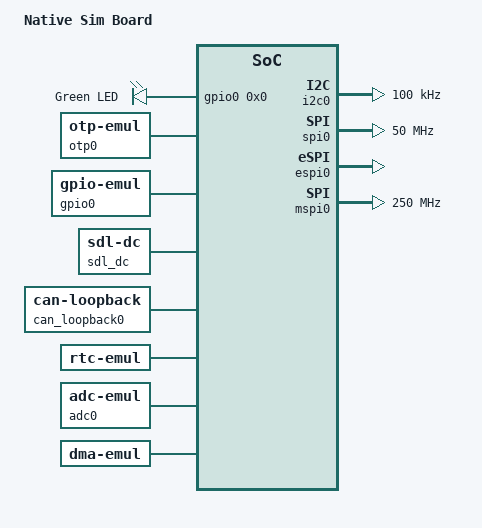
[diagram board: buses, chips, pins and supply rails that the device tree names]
/dts-v1/;

/* node '/' defined in zephyr/dts/common/skeleton.dtsi:9 */
/ {
	#address-cells = < 0x1 >;    /* in zephyr/dts/common/skeleton.dtsi:10 */
	#size-cells = < 0x1 >;       /* in zephyr/dts/common/skeleton.dtsi:11 */
	model = "Native Sim Board";  /* in zephyr/boards/native/native_sim/native_sim.dts:15 */
	compatible = "zephyr,posix"; /* in zephyr/boards/native/native_sim/native_sim.dts:16 */

	/* node '/chosen' defined in zephyr/dts/common/skeleton.dtsi:13 */
	chosen {
		zephyr,console = &uart0;                     /* in zephyr/boards/native/native_sim/native_sim.dts:19 */
		zephyr,shell-uart = &uart0;                  /* in zephyr/boards/native/native_sim/native_sim.dts:20 */
		zephyr,uart-mcumgr = &uart0;                 /* in zephyr/boards/native/native_sim/native_sim.dts:21 */
		zephyr,flash = &flash0;                      /* in zephyr/boards/native/native_sim/native_sim.dts:22 */
		zephyr,entropy = &rng;                       /* in zephyr/boards/native/native_sim/native_sim.dts:23 */
		zephyr,flash-controller = &flashcontroller0; /* in zephyr/boards/native/native_sim/native_sim.dts:24 */
		zephyr,display = &sdl_dc;                    /* in zephyr/boards/native/native_sim/native_sim.dts:25 */
		zephyr,canbus = &can_loopback0;              /* in zephyr/boards/native/native_sim/native_sim.dts:26 */
		zephyr,code-partition = &slot0_partition;    /* in zephyr/boards/native/native_sim/native_sim.dts:27 */
		zephyr,bt-hci = &bt_hci_userchan;            /* in zephyr/boards/native/native_sim/native_sim.dts:28 */
		zephyr,touch = &input_sdl_touch;             /* in zephyr/boards/native/native_sim/native_sim.dts:29 */
	};

	/* node '/aliases' defined in zephyr/dts/common/skeleton.dtsi:15 */
	aliases {
		codec0 = &audio_codec; /* in zephyr/boards/native/native_sim/native_sim.dts:33 */
		dmic0 = &dmic0;        /* in zephyr/boards/native/native_sim/native_sim.dts:34 */
		eeprom-0 = &eeprom0;   /* in zephyr/boards/native/native_sim/native_sim.dts:35 */
		i2c-0 = &i2c0;         /* in zephyr/boards/native/native_sim/native_sim.dts:36 */
		i2s-node0 = &i2s_rxtx; /* in zephyr/boards/native/native_sim/native_sim.dts:37 */
		spi-0 = &spi0;         /* in zephyr/boards/native/native_sim/native_sim.dts:38 */
		led0 = &led0;          /* in zephyr/boards/native/native_sim/native_sim.dts:39 */
		rtc = &rtc;            /* in zephyr/boards/native/native_sim/native_sim.dts:40 */
	};

	/* node '/leds' defined in zephyr/boards/native/native_sim/native_sim.dts:43 */
	leds: leds {
		compatible = "gpio-leds"; /* in zephyr/boards/native/native_sim/native_sim.dts:44 */

		/* node '/leds/led_0' defined in zephyr/boards/native/native_sim/native_sim.dts:46 */
		led0: led_0 {
			gpios = < &gpio0 0x0 0x0 >; /* in zephyr/boards/native/native_sim/native_sim.dts:47 */
			label = "Green LED";        /* in zephyr/boards/native/native_sim/native_sim.dts:48 */
		};
	};

	/* node '/cpus' defined in zephyr/boards/native/native_sim/native_sim.dts:52 */
	cpus {
		#address-cells = < 0x1 >; /* in zephyr/boards/native/native_sim/native_sim.dts:53 */
		#size-cells = < 0x0 >;    /* in zephyr/boards/native/native_sim/native_sim.dts:54 */

		/* node '/cpus/cpu@0' defined in zephyr/boards/native/native_sim/native_sim.dts:56 */
		cpu0: cpu@0 {
			compatible = "zephyr,native-sim-cpu"; /* in zephyr/boards/native/native_sim/native_sim.dts:57 */
			reg = < 0x0 >;                        /* in zephyr/boards/native/native_sim/native_sim.dts:58 */
		};
	};

	/* node '/flash-controller@0' defined in zephyr/boards/native/native_sim/native_sim.dts:62 */
	flashcontroller0: flash-controller@0 {
		compatible = "zephyr,sim-flash"; /* in zephyr/boards/native/native_sim/native_sim.dts:63 */
		reg = < 0x0 0x200000 >;          /* in zephyr/boards/native/native_sim/native_sim.dts:64 */
		ranges;                          /* in zephyr/boards/native/native_sim/native_sim.dts:65 */
		#address-cells = < 0x1 >;        /* in zephyr/boards/native/native_sim/native_sim.dts:67 */
		#size-cells = < 0x1 >;           /* in zephyr/boards/native/native_sim/native_sim.dts:68 */
		erase-value = < 0xff >;          /* in zephyr/boards/native/native_sim/native_sim.dts:69 */

		/* node '/flash-controller@0/flash@0' defined in zephyr/boards/native/native_sim/native_sim.dts:71 */
		flash0: flash@0 {
			status = "okay";               /* in zephyr/boards/native/native_sim/native_sim.dts:72 */
			compatible = "soc-nv-flash";   /* in zephyr/boards/native/native_sim/native_sim.dts:73 */
			erase-block-size = < 0x1000 >; /* in zephyr/boards/native/native_sim/native_sim.dts:74 */
			write-block-size = < 0x1 >;    /* in zephyr/boards/native/native_sim/native_sim.dts:75 */
			reg = < 0x0 0x200000 >;        /* in zephyr/boards/native/native_sim/native_sim.dts:76 */
			ranges = < 0x0 0x0 0x200000 >; /* in zephyr/boards/native/native_sim/native_sim.dts:77 */
			#address-cells = < 0x1 >;      /* in zephyr/boards/native/native_sim/native_sim.dts:78 */
			#size-cells = < 0x1 >;         /* in zephyr/boards/native/native_sim/native_sim.dts:79 */

			/* node '/flash-controller@0/flash@0/partitions' defined in zephyr/boards/native/native_sim/native_sim.dts:81 */
			partitions {
				ranges;                   /* in zephyr/boards/native/native_sim/native_sim.dts:82 */
				#address-cells = < 0x1 >; /* in zephyr/boards/native/native_sim/native_sim.dts:83 */
				#size-cells = < 0x1 >;    /* in zephyr/boards/native/native_sim/native_sim.dts:84 */

				/* node '/flash-controller@0/flash@0/partitions/partition@0' defined in zephyr/boards/native/native_sim/native_sim.dts:86 */
				boot_partition: partition@0 {
					compatible = "zephyr,mapped-partition"; /* in zephyr/boards/native/native_sim/native_sim.dts:87 */
					label = "mcuboot";                      /* in zephyr/boards/native/native_sim/native_sim.dts:88 */
					reg = < 0x0 0xc000 >;                   /* in zephyr/boards/native/native_sim/native_sim.dts:89 */
				};

				/* node '/flash-controller@0/flash@0/partitions/partition@c000' defined in zephyr/boards/native/native_sim/native_sim.dts:92 */
				slot0_partition: partition@c000 {
					compatible = "zephyr,mapped-partition"; /* in zephyr/boards/native/native_sim/native_sim.dts:93 */
					label = "image-0";                      /* in zephyr/boards/native/native_sim/native_sim.dts:94 */
					reg = < 0xc000 0x69000 >;               /* in zephyr/boards/native/native_sim/native_sim.dts:95 */
				};

				/* node '/flash-controller@0/flash@0/partitions/partition@75000' defined in zephyr/boards/native/native_sim/native_sim.dts:98 */
				slot1_partition: partition@75000 {
					compatible = "zephyr,mapped-partition"; /* in zephyr/boards/native/native_sim/native_sim.dts:99 */
					label = "image-1";                      /* in zephyr/boards/native/native_sim/native_sim.dts:100 */
					reg = < 0x75000 0x69000 >;              /* in zephyr/boards/native/native_sim/native_sim.dts:101 */
				};

				/* node '/flash-controller@0/flash@0/partitions/partition@de000' defined in zephyr/boards/native/native_sim/native_sim.dts:104 */
				scratch_partition: partition@de000 {
					compatible = "zephyr,mapped-partition"; /* in zephyr/boards/native/native_sim/native_sim.dts:105 */
					label = "image-scratch";                /* in zephyr/boards/native/native_sim/native_sim.dts:106 */
					reg = < 0xde000 0x1e000 >;              /* in zephyr/boards/native/native_sim/native_sim.dts:107 */
				};

				/* node '/flash-controller@0/flash@0/partitions/partition@fc000' defined in zephyr/boards/native/native_sim/native_sim.dts:110 */
				storage_partition: partition@fc000 {
					compatible = "zephyr,mapped-partition"; /* in zephyr/boards/native/native_sim/native_sim.dts:111 */
					label = "storage";                      /* in zephyr/boards/native/native_sim/native_sim.dts:112 */
					reg = < 0xfc000 0x4000 >;               /* in zephyr/boards/native/native_sim/native_sim.dts:113 */
				};
			};
		};
	};

	/* node '/eeprom' defined in zephyr/boards/native/native_sim/native_sim.dts:119 */
	eeprom0: eeprom {
		status = "okay";                  /* in zephyr/boards/native/native_sim/native_sim.dts:120 */
		compatible = "zephyr,sim-eeprom"; /* in zephyr/boards/native/native_sim/native_sim.dts:121 */
		size = < 0x8000 >;                /* in zephyr/boards/native/native_sim/native_sim.dts:122 */
	};

	/* node '/otp' defined in zephyr/boards/native/native_sim/native_sim.dts:125 */
	otp0: otp {
		compatible = "zephyr,otp-emul"; /* in zephyr/boards/native/native_sim/native_sim.dts:126 */
		size = < 0x400 >;               /* in zephyr/boards/native/native_sim/native_sim.dts:127 */
		status = "okay";                /* in zephyr/boards/native/native_sim/native_sim.dts:128 */
	};

	/* node '/i2c@100' defined in zephyr/boards/native/native_sim/native_sim.dts:131 */
	i2c0: i2c@100 {
		status = "okay";                           /* in zephyr/boards/native/native_sim/native_sim.dts:132 */
		compatible = "zephyr,i2c-emul-controller"; /* in zephyr/boards/native/native_sim/native_sim.dts:133 */
		clock-frequency = < 0x186a0 >;             /* in zephyr/boards/native/native_sim/native_sim.dts:134 */
		#address-cells = < 0x1 >;                  /* in zephyr/boards/native/native_sim/native_sim.dts:135 */
		#size-cells = < 0x0 >;                     /* in zephyr/boards/native/native_sim/native_sim.dts:136 */
		#forward-cells = < 0x1 >;                  /* in zephyr/boards/native/native_sim/native_sim.dts:137 */
		reg = < 0x100 0x4 >;                       /* in zephyr/boards/native/native_sim/native_sim.dts:138 */
	};

	/* node '/spi@200' defined in zephyr/boards/native/native_sim/native_sim.dts:141 */
	spi0: spi@200 {
		status = "okay";                           /* in zephyr/boards/native/native_sim/native_sim.dts:142 */
		compatible = "zephyr,spi-emul-controller"; /* in zephyr/boards/native/native_sim/native_sim.dts:143 */
		clock-frequency = < 0x2faf080 >;           /* in zephyr/boards/native/native_sim/native_sim.dts:144 */
		#address-cells = < 0x1 >;                  /* in zephyr/boards/native/native_sim/native_sim.dts:145 */
		#size-cells = < 0x0 >;                     /* in zephyr/boards/native/native_sim/native_sim.dts:146 */
		reg = < 0x200 0x4 >;                       /* in zephyr/boards/native/native_sim/native_sim.dts:147 */
	};

	/* node '/espi@300' defined in zephyr/boards/native/native_sim/native_sim.dts:150 */
	espi0: espi@300 {
		status = "okay";                            /* in zephyr/boards/native/native_sim/native_sim.dts:151 */
		compatible = "zephyr,espi-emul-controller"; /* in zephyr/boards/native/native_sim/native_sim.dts:152 */
		reg = < 0x300 0x4 >;                        /* in zephyr/boards/native/native_sim/native_sim.dts:153 */
		#address-cells = < 0x1 >;                   /* in zephyr/boards/native/native_sim/native_sim.dts:154 */
		#size-cells = < 0x0 >;                      /* in zephyr/boards/native/native_sim/native_sim.dts:155 */
	};

	/* node '/mspi@400' defined in zephyr/boards/native/native_sim/native_sim.dts:158 */
	mspi0: mspi@400 {
		status = "okay";                            /* in zephyr/boards/native/native_sim/native_sim.dts:159 */
		compatible = "zephyr,mspi-emul-controller"; /* in zephyr/boards/native/native_sim/native_sim.dts:160 */
		clock-frequency = < 0xee6b280 >;            /* in zephyr/boards/native/native_sim/native_sim.dts:161 */
		reg = < 0x400 0x4 >;                        /* in zephyr/boards/native/native_sim/native_sim.dts:162 */
		#address-cells = < 0x1 >;                   /* in zephyr/boards/native/native_sim/native_sim.dts:163 */
		#size-cells = < 0x0 >;                      /* in zephyr/boards/native/native_sim/native_sim.dts:164 */
	};

	/* node '/uart' defined in zephyr/boards/native/native_sim/native_sim.dts:167 */
	uart0: uart {
		status = "okay";                       /* in zephyr/boards/native/native_sim/native_sim.dts:168 */
		compatible = "zephyr,native-pty-uart"; /* in zephyr/boards/native/native_sim/native_sim.dts:169 */
		current-speed = < 0x0 >;               /* in zephyr/boards/native/native_sim/native_sim.dts:173 */
	};

	/* node '/uart_1' defined in zephyr/boards/native/native_sim/native_sim.dts:176 */
	uart1: uart_1 {
		status = "disabled";                   /* in zephyr/boards/native/native_sim/native_sim.dts:177 */
		compatible = "zephyr,native-pty-uart"; /* in zephyr/boards/native/native_sim/native_sim.dts:178 */
		current-speed = < 0x0 >;               /* in zephyr/boards/native/native_sim/native_sim.dts:182 */
	};

	/* node '/rng' defined in zephyr/boards/native/native_sim/native_sim.dts:185 */
	rng: rng {
		status = "okay";                      /* in zephyr/boards/native/native_sim/native_sim.dts:186 */
		compatible = "zephyr,native-sim-rng"; /* in zephyr/boards/native/native_sim/native_sim.dts:187 */
	};

	/* node '/counter' defined in zephyr/boards/native/native_sim/native_sim.dts:190 */
	counter0: counter {
		status = "okay";                          /* in zephyr/boards/native/native_sim/native_sim.dts:191 */
		compatible = "zephyr,native-sim-counter"; /* in zephyr/boards/native/native_sim/native_sim.dts:192 */
		#counter-capture-cells = < 0x2 >;         /* in zephyr/boards/native/native_sim/native_sim.dts:193 */
	};

	/* node '/gpio_emul' defined in zephyr/boards/native/native_sim/native_sim.dts:196 */
	gpio0: gpio_emul {
		status = "okay";                 /* in zephyr/boards/native/native_sim/native_sim.dts:197 */
		compatible = "zephyr,gpio-emul"; /* in zephyr/boards/native/native_sim/native_sim.dts:198 */
		rising-edge;                     /* in zephyr/boards/native/native_sim/native_sim.dts:199 */
		falling-edge;                    /* in zephyr/boards/native/native_sim/native_sim.dts:200 */
		high-level;                      /* in zephyr/boards/native/native_sim/native_sim.dts:201 */
		low-level;                       /* in zephyr/boards/native/native_sim/native_sim.dts:202 */
		gpio-controller;                 /* in zephyr/boards/native/native_sim/native_sim.dts:203 */
		#gpio-cells = < 0x2 >;           /* in zephyr/boards/native/native_sim/native_sim.dts:204 */
		phandle = < 0x1 >;               /* in zephyr/boards/native/native_sim/native_sim.dts:47 */
	};

	/* node '/udc0' defined in zephyr/boards/native/native_sim/native_sim.dts:207 */
	zephyr_udc0: udc0 {
		compatible = "zephyr,native-posix-udc"; /* in zephyr/boards/native/native_sim/native_sim.dts:208 */
	};

	/* node '/sdl_dc' defined in zephyr/boards/native/native_sim/native_sim.dts:211 */
	sdl_dc: sdl_dc {
		compatible = "zephyr,sdl-dc"; /* in zephyr/boards/native/native_sim/native_sim.dts:212 */
		pixel-format = < 0x8 >;       /* in zephyr/boards/native/native_sim/native_sim.dts:213 */
		height = < 0xf0 >;            /* in zephyr/boards/native/native_sim/native_sim.dts:214 */
		width = < 0x140 >;            /* in zephyr/boards/native/native_sim/native_sim.dts:215 */
		phandle = < 0x2 >;            /* in zephyr/boards/native/native_sim/native_sim.dts:220 */
	};

	/* node '/input-sdl-touch' defined in zephyr/boards/native/native_sim/native_sim.dts:218 */
	input_sdl_touch: input-sdl-touch {
		compatible = "zephyr,input-sdl-touch"; /* in zephyr/boards/native/native_sim/native_sim.dts:219 */
		display = < &sdl_dc >;                 /* in zephyr/boards/native/native_sim/native_sim.dts:220 */
	};

	/* node '/can_loopback0' defined in zephyr/boards/native/native_sim/native_sim.dts:223 */
	can_loopback0: can_loopback0 {
		status = "okay";                    /* in zephyr/boards/native/native_sim/native_sim.dts:224 */
		compatible = "zephyr,can-loopback"; /* in zephyr/boards/native/native_sim/native_sim.dts:225 */
	};

	/* node '/can' defined in zephyr/boards/native/native_sim/native_sim.dts:228 */
	can0: can {
		status = "disabled";                    /* in zephyr/boards/native/native_sim/native_sim.dts:229 */
		compatible = "zephyr,native-linux-can"; /* in zephyr/boards/native/native_sim/native_sim.dts:230 */
		host-interface = "zcan0";               /* in zephyr/boards/native/native_sim/native_sim.dts:234 */
	};

	/* node '/rtc' defined in zephyr/boards/native/native_sim/native_sim.dts:237 */
	rtc: rtc {
		status = "okay";                /* in zephyr/boards/native/native_sim/native_sim.dts:238 */
		compatible = "zephyr,rtc-emul"; /* in zephyr/boards/native/native_sim/native_sim.dts:239 */
		alarms-count = < 0x2 >;         /* in zephyr/boards/native/native_sim/native_sim.dts:240 */
	};

	/* node '/adc' defined in zephyr/boards/native/native_sim/native_sim.dts:243 */
	adc0: adc {
		compatible = "zephyr,adc-emul"; /* in zephyr/boards/native/native_sim/native_sim.dts:244 */
		nchannels = < 0x2 >;            /* in zephyr/boards/native/native_sim/native_sim.dts:245 */
		#io-channel-cells = < 0x1 >;    /* in zephyr/boards/native/native_sim/native_sim.dts:246 */
		status = "okay";                /* in zephyr/boards/native/native_sim/native_sim.dts:247 */
	};

	/* node '/audio_codec' defined in zephyr/boards/native/native_sim/native_sim.dts:250 */
	audio_codec: audio_codec {
		compatible = "zephyr,dummy-codec"; /* in zephyr/boards/native/native_sim/native_sim.dts:251 */
		status = "okay";                   /* in zephyr/boards/native/native_sim/native_sim.dts:252 */
	};

	/* node '/dmic0' defined in zephyr/boards/native/native_sim/native_sim.dts:255 */
	dmic0: dmic0 {
		compatible = "zephyr,native-sim-dmic"; /* in zephyr/boards/native/native_sim/native_sim.dts:256 */
		status = "okay";                       /* in zephyr/boards/native/native_sim/native_sim.dts:257 */
	};

	/* node '/i2s_rx' defined in zephyr/boards/native/native_sim/native_sim.dts:260 */
	i2s_rx0: i2s_rx {
		compatible = "zephyr,native-sim-i2s"; /* in zephyr/boards/native/native_sim/native_sim.dts:261 */
		status = "okay";                      /* in zephyr/boards/native/native_sim/native_sim.dts:262 */
		stream-direction = "rx";              /* in zephyr/boards/native/native_sim/native_sim.dts:263 */
	};

	/* node '/i2s_rxtx' defined in zephyr/boards/native/native_sim/native_sim.dts:266 */
	i2s_rxtx: i2s_rxtx {
		compatible = "zephyr,native-sim-i2s"; /* in zephyr/boards/native/native_sim/native_sim.dts:267 */
		status = "okay";                      /* in zephyr/boards/native/native_sim/native_sim.dts:268 */
		stream-direction = "both";            /* in zephyr/boards/native/native_sim/native_sim.dts:269 */
	};

	/* node '/i2s_tx' defined in zephyr/boards/native/native_sim/native_sim.dts:272 */
	i2s_tx0: i2s_tx {
		compatible = "zephyr,native-sim-i2s"; /* in zephyr/boards/native/native_sim/native_sim.dts:273 */
		status = "okay";                      /* in zephyr/boards/native/native_sim/native_sim.dts:274 */
		stream-direction = "tx";              /* in zephyr/boards/native/native_sim/native_sim.dts:275 */
	};

	/* node '/dma' defined in zephyr/boards/native/native_sim/native_sim.dts:278 */
	dma: dma {
		compatible = "zephyr,dma-emul"; /* in zephyr/boards/native/native_sim/native_sim.dts:279 */
		#dma-cells = < 0x1 >;           /* in zephyr/boards/native/native_sim/native_sim.dts:280 */
		stack-size = < 0x1000 >;        /* in zephyr/boards/native/native_sim/native_sim.dts:281 */
	};

	/* node '/bt_hci_userchan' defined in zephyr/boards/native/native_sim/native_sim.dts:284 */
	bt_hci_userchan: bt_hci_userchan {
		compatible = "zephyr,bt-hci-userchan"; /* in zephyr/boards/native/native_sim/native_sim.dts:285 */
		status = "okay";                       /* in zephyr/boards/native/native_sim/native_sim.dts:286 */
	};

	/* node '/performance-states' defined in zephyr/boards/native/native_sim/native_sim.dts:289 */
	performance-states {

		/* node '/performance-states/pstate_0' defined in zephyr/boards/native/native_sim/native_sim.dts:290 */
		pstate_0: pstate_0 {
			compatible = "zephyr,native-sim-pstate"; /* in zephyr/boards/native/native_sim/native_sim.dts:291 */
			load-threshold = < 0x32 >;               /* in zephyr/boards/native/native_sim/native_sim.dts:292 */
			pstate-id = < 0x0 >;                     /* in zephyr/boards/native/native_sim/native_sim.dts:293 */
		};

		/* node '/performance-states/pstate_1' defined in zephyr/boards/native/native_sim/native_sim.dts:296 */
		pstate_1: pstate_1 {
			compatible = "zephyr,native-sim-pstate"; /* in zephyr/boards/native/native_sim/native_sim.dts:297 */
			load-threshold = < 0x14 >;               /* in zephyr/boards/native/native_sim/native_sim.dts:298 */
			pstate-id = < 0x1 >;                     /* in zephyr/boards/native/native_sim/native_sim.dts:299 */
		};

		/* node '/performance-states/pstate_2' defined in zephyr/boards/native/native_sim/native_sim.dts:302 */
		pstate_2: pstate_2 {
			compatible = "zephyr,native-sim-pstate"; /* in zephyr/boards/native/native_sim/native_sim.dts:303 */
			load-threshold = < 0x0 >;                /* in zephyr/boards/native/native_sim/native_sim.dts:304 */
			pstate-id = < 0x2 >;                     /* in zephyr/boards/native/native_sim/native_sim.dts:305 */
		};
	};

	/* node '/zeth0' defined in zephyr/boards/native/native_sim/native_sim.dts:309 */
	zeth0: zeth0 {
		compatible = "zephyr,native-tap";               /* in zephyr/boards/native/native_sim/native_sim.dts:310 */
		status = "okay";                                /* in zephyr/boards/native/native_sim/native_sim.dts:311 */
		zephyr,random-mac-address;                      /* in zephyr/boards/native/native_sim/native_sim.dts:312 */
		zephyr,mac-address-prefix = [ 00 00 5E 00 53 ]; /* in zephyr/boards/native/native_sim/native_sim.dts:313 */
		host-interface = "zeth";                        /* in zephyr/boards/native/native_sim/native_sim.dts:314 */

		/* node '/zeth0/ptp_clock' defined in zephyr/boards/native/native_sim/native_sim.dts:316 */
		ptp_clock: ptp_clock {
			compatible = "zephyr,native-ptp-clock"; /* in zephyr/boards/native/native_sim/native_sim.dts:317 */
			status = "okay";                        /* in zephyr/boards/native/native_sim/native_sim.dts:318 */
		};
	};
};
